# PIC16LF1619 register map
Vendor: Microchip
Registers are 8-bit, read-write, reset 0x0 unless marked. A register's access mark holds for its fields unless they carry their own. Addresses are absolute, and some are shared; only a register's first bit layout is shown; [hi:lo] are bit positions; {n}, {i} and the like mark numbered series.

## pwm
0x617 PWM3DCL reset not defined — (power-on value xx------)
  [7:6] DC
0x618 PWM3DCH reset not defined — (power-on value xxxxxxxx)
  [7:0] DC
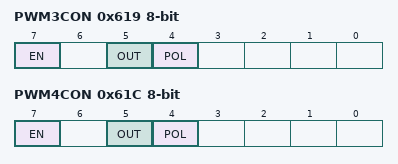
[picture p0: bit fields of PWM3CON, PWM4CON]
0x619 PWM3CON
  [7] EN, [5] OUT ro, [4] POL
0x61A PWM4DCL reset not defined — (power-on value xx------)
  [7:6] DC
0x61B PWM4DCH reset not defined — (power-on value xxxxxxxx)
  [7:0] DC
0x61C PWM4CON
  [7] EN, [5] OUT ro, [4] POL

## wg_cwg
0x691 CWG1DBR
  [5:0] DBR
0x692 CWG1DBF
  [5:0] DBF
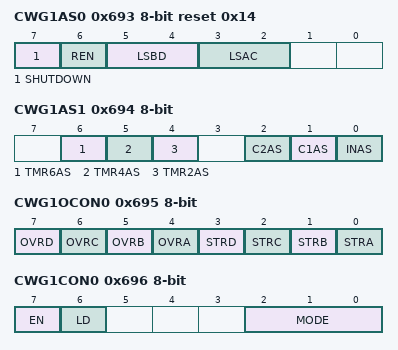
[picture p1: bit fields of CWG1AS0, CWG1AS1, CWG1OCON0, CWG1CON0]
0x693 CWG1AS0 reset 0x14
  [7] SHUTDOWN, [6] REN, [5:4] LSBD, [3:2] LSAC
0x694 CWG1AS1
  [6] TMR6AS, [5] TMR4AS, [4] TMR2AS, [2] C2AS, [1] C1AS, [0] INAS
0x695 CWG1OCON0
  [7] OVRD, [6] OVRC, [5] OVRB, [4] OVRA, [3] STRD, [2] STRC, [1] STRB, [0] STRA
0x696 CWG1CON0
  [7] EN, [6] LD, [2:0] MODE
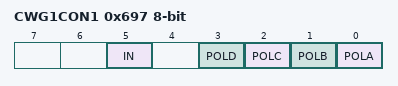
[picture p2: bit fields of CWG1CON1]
0x697 CWG1CON1
  [5] IN ro, [3] POLD, [2] POLC, [1] POLB, [0] POLA
0x699 CWG1CLKCON
  [0] CS
0x69A CWG1ISM
  [3:0] IS

## wdt_windowed
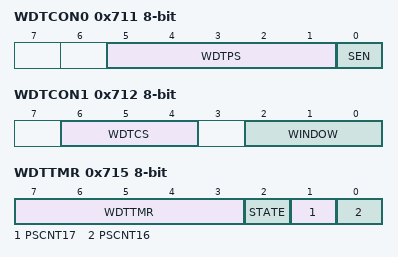
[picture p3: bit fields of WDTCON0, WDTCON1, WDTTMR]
0x711 WDTCON0 reset not defined — (power-on value --qqqqq0)
  [5:1] WDTPS, [0] SEN
0x712 WDTCON1 reset not defined — (power-on value -qqq-qqq)
  [6:4] WDTCS, [2:0] WINDOW
0x713 WDTPSL ro
  [7:0] PSCNT
0x714 WDTPSH ro
  [7:0] PSCNT
0x715 WDTTMR ro reset not defined — (power-on value xxxxx000)
  [7:3] WDTTMR, [2] STATE, [1] PSCNT17, [0] PSCNT16

## dma_nvm
0x718 SCANLADRL
  [7:0] LADR
0x719 SCANLADRH
  [7:0] LADR
0x71A SCANHADRL reset 0xFF
  [7:0] HADR
0x71B SCANHADRH reset 0xFF
  [7:0] HADR
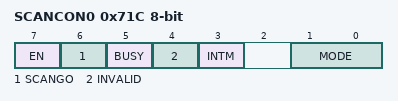
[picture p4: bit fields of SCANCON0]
0x71C SCANCON0
  [7] EN, [6] SCANGO, [5] BUSY ro, [4] INVALID ro, [3] INTM, [1:0] MODE
0x71D SCANTRIG
  [3:0] TSEL

## math_progcrc
0x791 CRCDATL reset not defined — (power-on value xxxxxxxx)
  [7:0] DAT
0x792 CRCDATH reset not defined — (power-on value xxxxxxxx)
  [7:0] DAT
0x793 CRCACCL
  [7:0] ACC
0x794 CRCACCH
  [7:0] ACC
0x795 CRCSHIFTL
  [7:0] SHIFT
0x796 CRCSHIFTH
  [7:0] SHIFT
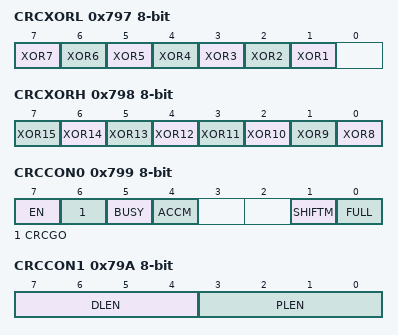
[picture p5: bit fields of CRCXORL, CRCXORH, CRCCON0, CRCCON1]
0x797 CRCXORL reset not defined — (power-on value xxxxxxx-)
  [n] XOR{n} (n=1..7)
0x798 CRCXORH reset not defined — (power-on value xxxxxxxx)
  [n-8] XOR{n} (n=8..15)
0x799 CRCCON0
  [7] EN, [6] CRCGO, [5] BUSY ro, [4] ACCM, [1] SHIFTM, [0] FULL ro
0x79A CRCCON1
  [7:4] DLEN, [3:0] PLEN

## tmr_angular
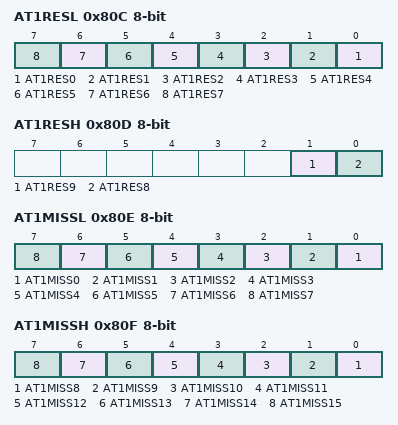
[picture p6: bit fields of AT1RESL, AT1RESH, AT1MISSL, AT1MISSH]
0x80C AT1RESL reset not defined — (power-on value xxxxxxxx)
  [n] AT1RES{n} (n=0..7)
0x80D AT1RESH reset not defined — (power-on value ------xx)
  [1] AT1RES9, [0] AT1RES8
0x80E AT1MISSL reset not defined — (power-on value xxxxxxxx)
  [n] AT1MISS{n} (n=0..7)
0x80F AT1MISSH reset not defined — (power-on value xxxxxxxx)
  [n-8] AT1MISS{n} (n=8..15)
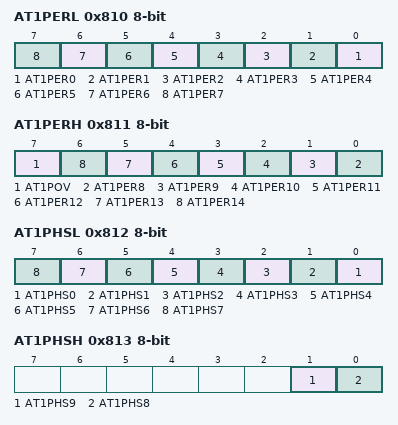
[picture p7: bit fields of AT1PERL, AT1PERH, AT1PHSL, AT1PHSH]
0x810 AT1PERL ro reset not defined — (power-on value xxxxxxxx)
  [n] AT1PER{n} (n=0..7)
0x811 AT1PERH ro reset not defined — (power-on value xxxxxxxx)
  [7] AT1POV, [n-8] AT1PER{n} (n=8..14)
0x812 AT1PHSL ro reset not defined — (power-on value xxxxxxxx)
  [n] AT1PHS{n} (n=0..7)
0x813 AT1PHSH ro reset not defined — (power-on value ------xx)
  [1] AT1PHS9, [0] AT1PHS8
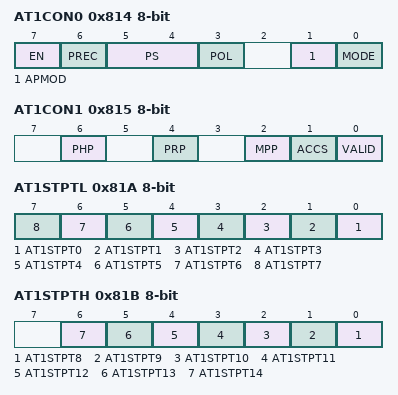
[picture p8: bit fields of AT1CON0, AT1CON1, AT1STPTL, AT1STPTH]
0x814 AT1CON0 reset not defined — (power-on value 0x000-00)
  [7] EN, [6] PREC, [5:4] PS, [3] POL, [1] APMOD, [0] MODE
0x815 AT1CON1
  [6] PHP, [4] PRP, [2] MPP, [1] ACCS ro, [0] VALID ro
0x81A AT1STPTL reset not defined — (power-on value xxxxxxxx)
  [n] AT1STPT{n} (n=0..7)
0x81B AT1STPTH reset not defined — (power-on value -xxxxxxx)
  [n-8] AT1STPT{n} (n=8..14)
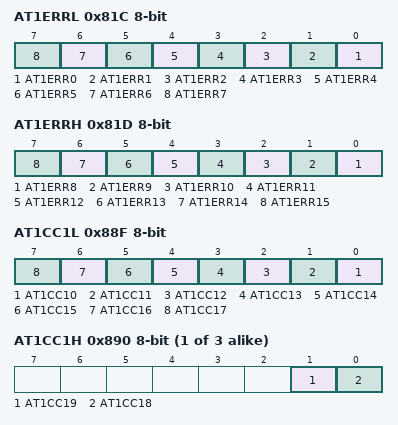
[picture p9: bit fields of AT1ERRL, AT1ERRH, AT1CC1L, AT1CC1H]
0x81C AT1ERRL ro reset not defined — (power-on value xxxxxxxx)
  [n] AT1ERR{n} (n=0..7)
0x81D AT1ERRH ro reset not defined — (power-on value xxxxxxxx)
  [n-8] AT1ERR{n} (n=8..15)
0x88C AT1CLK
  [0] CS
0x88D AT1SIG
  [2:0] SSEL
0x88E AT1CSEL1
  [2:0] CP1S
0x88F AT1CC1L
  [n-10] AT1CC{n} (n=10..17)
{0x88C+4i} AT1CC{i}H (i=1..3)
  [1] AT1CC{10i+9}, [0] AT1CC{10i+8}
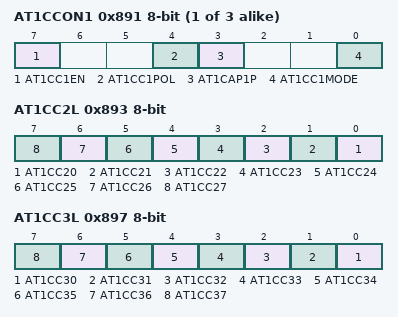
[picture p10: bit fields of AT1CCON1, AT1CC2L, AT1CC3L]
{0x88D+4i} AT1CCON{i} (i=1..3)
  [7] AT1CC{i}EN, [4] AT1CC{i}POL, [3] AT1CAP{i}P, [0] AT1CC{i}MODE
0x892 AT1CSEL2
  [2:0] AT1CP2S
0x893 AT1CC2L
  [n-20] AT1CC{n} (n=20..27)
0x896 AT1CSEL3
  [2:0] AT1CP3S
0x897 AT1CC3L
  [n-30] AT1CC{n} (n=30..37)

## tmr_smt
0xD8C SMT1TMRL
  [7:0] SMT1TMR
0xD8D SMT1TMRH
  [7:0] SMT1TMR
0xD8E SMT1TMRU
  [7:0] SMT1TMR
0xD8F SMT1CPRL ro reset not defined — (power-on value xxxxxxxx)
  [7:0] SMT1CPR
0xD90 SMT1CPRH ro reset not defined — (power-on value xxxxxxxx)
  [7:0] SMT1CPR
0xD91 SMT1CPRU ro reset not defined — (power-on value xxxxxxxx)
  [7:0] SMT1CPR
0xD92 SMT1CPWL ro reset not defined — (power-on value xxxxxxxx)
  [7:0] SMT1CPW
0xD93 SMT1CPWH ro reset not defined — (power-on value xxxxxxxx)
  [7:0] SMT1CPW
0xD94 SMT1CPWU ro reset not defined — (power-on value xxxxxxxx)
  [7:0] SMT1CPW
0xD95 SMT1PRL reset 0xFF
  [7:0] SMT1PR
0xD96 SMT1PRH reset 0xFF
  [7:0] SMT1PR
0xD97 SMT1PRU reset 0xFF
  [7:0] SMT1PR
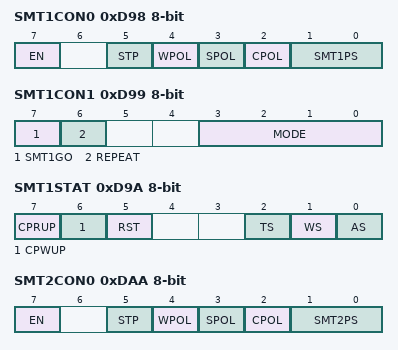
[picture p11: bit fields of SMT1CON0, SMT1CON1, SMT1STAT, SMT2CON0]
0xD98 SMT1CON0
  [7] EN, [5] STP, [4] WPOL, [3] SPOL, [2] CPOL, [1:0] SMT1PS
0xD99 SMT1CON1
  [7] SMT1GO, [6] REPEAT, [3:0] MODE
0xD9A SMT1STAT
  [7] CPRUP, [6] CPWUP, [5] RST, [2] TS ro, [1] WS ro, [0] AS ro
0xD9B SMT1CLK
  [2:0] CSEL
0xD9C SMT1SIG
  [4:0] SSEL
0xD9D SMT1WIN
  [4:0] WSEL
0xD9E SMT2TMRL
  [7:0] SMT2TMR
0xD9F SMT2TMRH
  [7:0] SMT2TMR
0xDA0 SMT2TMRU
  [7:0] SMT2TMR
0xDA1 SMT2CPRL ro reset not defined — (power-on value xxxxxxxx)
  [7:0] SMT2CPR
0xDA2 SMT2CPRH ro reset not defined — (power-on value xxxxxxxx)
  [7:0] SMT2CPR
0xDA3 SMT2CPRU ro reset not defined — (power-on value xxxxxxxx)
  [7:0] SMT2CPR
0xDA4 SMT2CPWL ro reset not defined — (power-on value xxxxxxxx)
  [7:0] SMT2CPW
0xDA5 SMT2CPWH ro reset not defined — (power-on value xxxxxxxx)
  [7:0] SMT2CPW
0xDA6 SMT2CPWU ro reset not defined — (power-on value xxxxxxxx)
  [7:0] SMT2CPW
0xDA7 SMT2PRL reset 0xFF
  [7:0] SMT2PR
0xDA8 SMT2PRH reset 0xFF
  [7:0] SMT2PR
0xDA9 SMT2PRU reset 0xFF
  [7:0] SMT2PR
0xDAA SMT2CON0
  [7] EN, [5] STP, [4] WPOL, [3] SPOL, [2] CPOL, [1:0] SMT2PS
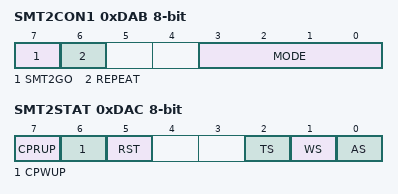
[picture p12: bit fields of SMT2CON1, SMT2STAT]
0xDAB SMT2CON1
  [7] SMT2GO, [6] REPEAT, [3:0] MODE
0xDAC SMT2STAT
  [7] CPRUP, [6] CPWUP, [5] RST, [2] TS ro, [1] WS ro, [0] AS ro
0xDAD SMT2CLK
  [2:0] CSEL
0xDAE SMT2SIG
  [4:0] SSEL
0xDAF SMT2WIN
  [4:0] WSEL

## CLC
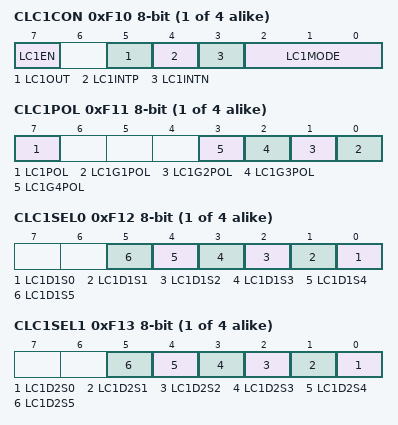
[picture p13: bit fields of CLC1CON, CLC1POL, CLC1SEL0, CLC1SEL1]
{0xF06+0xA*i} CLC{i}CON (i=1..4) — Configurable logic cell control
  [7] LC{i}EN, [5] LC{i}OUT ro, [4] LC{i}INTP, [3] LC{i}INTN, [2:0] LC{i}MODE
{0xF07+0xA*i} CLC{i}POL reset not defined (i=1..4) — Polarity control (power-on value 0---xxxx)
  [7] LC{i}POL, [n-1] LC{i}G{n}POL (n=1..4)
{0xF08+0xA*i} CLC{i}SEL0 reset not defined (i=1..4) — Input select register 1 (power-on value --xxxxxx)
  [n] LC{i}D1S{n} (n=0..5)
{0xF09+0xA*i} CLC{i}SEL1 reset not defined (i=1..4) — Input select register 1 (power-on value --xxxxxx)
  [n] LC{i}D2S{n} (n=0..5)
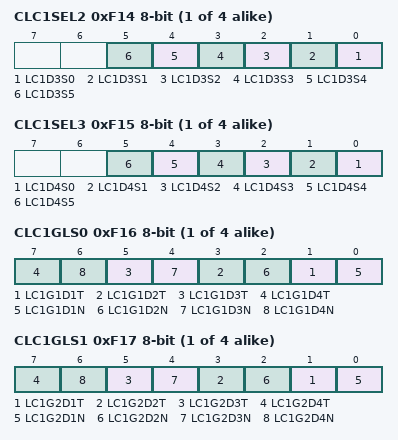
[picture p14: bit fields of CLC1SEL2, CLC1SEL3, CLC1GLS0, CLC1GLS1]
{0xF0A+0xA*i} CLC{i}SEL2 reset not defined (i=1..4) — Input select register 2 (power-on value --xxxxxx)
  [n] LC{i}D3S{n} (n=0..5)
{0xF0B+0xA*i} CLC{i}SEL3 reset not defined (i=1..4) — Input select register 3 (power-on value --xxxxxx)
  [n] LC{i}D4S{n} (n=0..5)
{0xF0C+0xA*i} CLC{i}GLS0 reset not defined (i=1..4) — Gate logic select register 0 (power-on value xxxxxxxx)
  [2n-1] LC{i}G1D{n}T (n=1..4), [2n-2] LC{i}G1D{n}N (n=1..4)
{0xF0D+0xA*i} CLC{i}GLS1 reset not defined (i=1..4) — Gate logic select register 1 (power-on value xxxxxxxx)
  [2n-1] LC{i}G2D{n}T (n=1..4), [2n-2] LC{i}G2D{n}N (n=1..4)
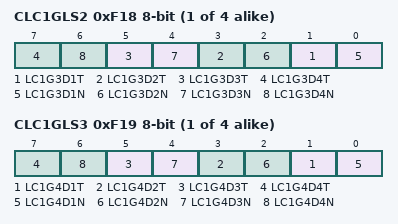
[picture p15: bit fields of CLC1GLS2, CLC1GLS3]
{0xF0E+0xA*i} CLC{i}GLS2 reset not defined (i=1..4) — Gate logic select register 2 (power-on value xxxxxxxx)
  [2n-1] LC{i}G3D{n}T (n=1..4), [2n-2] LC{i}G3D{n}N (n=1..4)
{0xF0F+0xA*i} CLC{i}GLS3 reset not defined (i=1..4) — Gate logic select register 3 (power-on value xxxxxxxx)
  [2n-1] LC{i}G4D{n}T (n=1..4), [2n-2] LC{i}G4D{n}N (n=1..4)
